# M0519AE_v1 register map
File version: 1.0
Registers are 32-bit, read-write, reset 0x0 unless marked. A register's access mark holds for its fields unless they carry their own. Offsets are from the block's base; [hi:lo] are bit positions; {n}, {i} and the like mark numbered series.

## CLK — CLK Register Map
Base 0x50000200
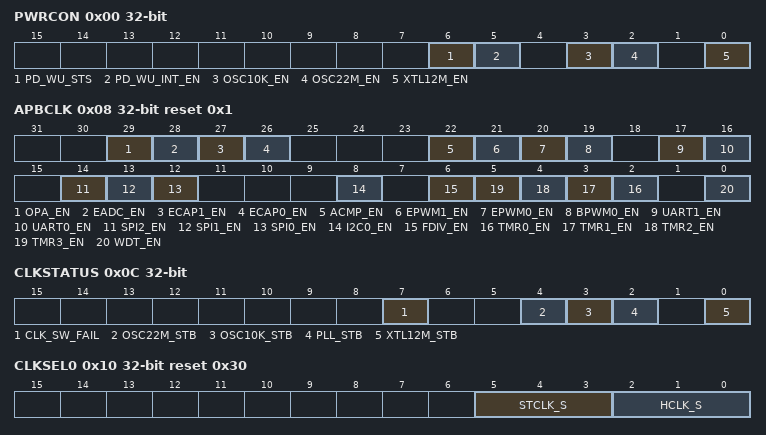
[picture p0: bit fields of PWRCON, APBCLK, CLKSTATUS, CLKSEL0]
0x00 PWRCON (reset mask 0xFFFFFFF0) — System Power-down Control Register
  [6] PD_WU_STS — Power-down Mode Wake-up Interrupt Status. Set by "power down wake up event", it indicates that resume from Power-down mode. Write 1 to clear the bit to zero. Note: This bit is working only if PD_WU_INT_EN (PWRCON[5]) set to 1.
  [5] PD_WU_INT_EN — Power-down Mode Wake-up Interrupt Enable Bit (Write Protect). Note1: The interrupt will occur when both PD_WU_STS and PD_WU_INT_EN are high. Note2: This bit is write protected bit. Refer to the REGWRPROT register.
    0=Power-down mode wake-up interrupt Disabled; 1=Power-down mode wake-up interrupt Enabled
  [3] OSC10K_EN — Internal 10 kHz Oscillator Enable Bit (Write Protect). Note: This bit is write protected bit. Refer to the REGWRPROT register.
    0=10 kHz Oscillation Disabled; 1=10 kHz Oscillation Enabled
  [2] OSC22M_EN — Internal 22.1184 MHz Oscillator Enable Bit (Write Protect). Note: This bit is write protected bit. Refer to the REGWRPROT register.
    0=22.1184 MHz Oscillation Disabled; 1=22.1184 MHz Oscillation Enabled
  [0] XTL12M_EN — External 4~24 MHz Crystal Enable Bit (Write Protect). The bit default value is set by flash controller user configuration register CFOSC (Config0[26:24]). When the default clock source is from external 4~24 MHz crystal, this bit is set to 1 automatically. Note: This bit is write protected bit. Refer to the REGWRPROT register.
    0=External 4~24 MHz crystal Disabled; 1=External 4~24 MHz crystal Enabled
0x04 AHBCLK reset 0x5 — AHB Devices Clock Enable Control Register
  [4] HDIV_EN — Hardware Divider Controller Clock Enable Bit
    0=Hardware Divider engine clock Disabled; 1=Hardware Divider engine clock Enabled
0x08 APBCLK reset 0x1 — APB Devices Clock Enable Control Register
  [29] OPA_EN — OPA0 and OPA1 Clock Enable Bit
    0=OPA0 and OPA1 clock Disabled; 1=OPA0 and OPA1 clock Enabled
  [28] EADC_EN — EADC Clock Enable Bit
    0=EADC clock Disabled; 1=EADC clock Enabled
  [27] ECAP1_EN — Enhanced Input Capture 1 Clock Enable Bit
    0=Enhanced input capture 1 clock Disabled; 1=Enhanced input capture 1 clock Enabled
  [26] ECAP0_EN — Enhanced Input Capture 0 Clock Enable Bit
    0=Enhanced input capture 0 clock Disabled; 1=Enhanced input capture 0 clock Enabled
  [22] ACMP_EN — Analog Comparator Clock Enable Bit
    0=Analog comparator clock Disabled; 1=Analog comparator clock Enabled
  [21] EPWM1_EN — Enhanced PWM1 Clock Enable Bit
    0=Enhanced PWM1 clock Disabled; 1=Enhanced PWM1 clock Enabled
  [20] EPWM0_EN — Enhanced PWM0 Clock Enable Bit
    0=Enhanced PWM0 clock Disabled; 1=Enhanced PWM0 clock Enabled
  [19] BPWM0_EN — Basic PWM0 Clock Enable Bit
    0=Basic PWM0 clock Disabled; 1=Basic PWM0 clock Enabled
  [17] UART1_EN — UART1 Clock Enable Bit
    0=UART1 clock Disabled; 1=UART1 clock Enabled
  [16] UART0_EN — UART0 Clock Enable Bit
    0=UART0 clock Disabled; 1=UART0 clock Enabled
  [14] SPI2_EN — SPI2 Clock Enable Bit
    0=SPI2 clock Disabled; 1=SPI2 clock Enabled
  [13] SPI1_EN — SPI1 Clock Enable Bit
    0=SPI1 clock Disabled; 1=SPI1 clock Enabled
  [12] SPI0_EN — SPI0 Clock Enable Bit
    0=SPI0 clock Disabled; 1=SPI0 clock Enabled
  [8] I2C0_EN — I2C0 Clock Enable Bit
    0=I2C0 clock Disabled; 1=I2C0 clock Enabled
  [6] FDIV_EN — Frequency Divider Output Clock Enable Bit
    0=Frequency divider output clock Disabled; 1=Frequency divider output clock Enabled
  [n+2] TMR{n}_EN (n=0..3) — Timer{n} Clock Enable Bit
    0=Timer{n} clock Disabled; 1=Timer{n} clock Enabled
  [0] WDT_EN — Watchdog Timer Clock Enable Bit (Write Protect). Note: This bit is write protected bit. Refer to the REGWRPROT register.
    0=Watchdog Timer clock Disabled; 1=Watchdog Timer clock Enabled
0x0C CLKSTATUS ro (reset mask 0xFFFFFF00) — Clock Status Monitor Register
  [7] CLK_SW_FAIL — Clock Switching Fail Flag (Read Only). This bit is an index that if current system clock source is match as user defined at HCLK_S (CLKSEL0[2:0]). When user switch system clock, the system clock source will keep old clock until the new clock is stable. During the period that waiting new clock stable, this bit will be an index shows system clock source is not match as user wanted.
    0=Clock switching success; 1=Clock switching failure
  [4] OSC22M_STB — Internal 22.1184M Hz Oscillator Clock Source Stable Flag (Read Only)
    0=Internal 22.1184M Hz oscillator clock is not stable or disabled; 1=Internal 22.1184M Hz oscillator clock is stable and enabled
  [3] OSC10K_STB — Internal 10k Hz Clock Source Stable Flag (Read Only)
    0=Internal 10k Hz oscillator clock is not stable or disabled; 1=Internal 10k Hz oscillator clock is stable and enabled
  [2] PLL_STB — PLL Clock Source Stable Flag (Read Only)
    0=PLL clock is not stable or disabled; 1=PLL clock is stable in normal mode
  [0] XTL12M_STB — External 4~24 MHz Crystal Clock Source Stable Flag (Read Only)
    0=External 4~24 MHz crystal clock is not stable or disabled; 1=External 4~24 MHz crystal clock is stable and enabled
0x10 CLKSEL0 reset 0x30 (reset mask 0xFFFFFFF0) — Clock Source Select Control Register 0
  [5:3] STCLK_S — Cortex-M0 SysTick Clock Source Selection (Write Protect)
    0=Clock source from external 4~24 MHz crystal clock; 2=Clock source from external 4~24 MHz crystal clock/2; 3=Clock source from HCLK/2; 7=Clock source from internal 22.1184 MHz oscillator clock/2
  [2:0] HCLK_S — HCLK Clock Source Selection (Write Protect). Before clock switching, the related clock sources (both pre-select and new-select) must be turn on. The 3-bit default value is reloaded from the value of CFOSC (Config0[26:24]) in user configuration register of Flash controller by any reset. Therefore the default value is either 000b or 111b. Note: These bits are write protected bits. Refer to the REGWRPROT register.
    0=Clock source from external 4~24 MHz crystal clock; 2=Clock source from PLL clock; 3=Clock source from internal 10 kHz oscillator clock; 7=Clock source from internal 22.1184 MHz oscillator clock
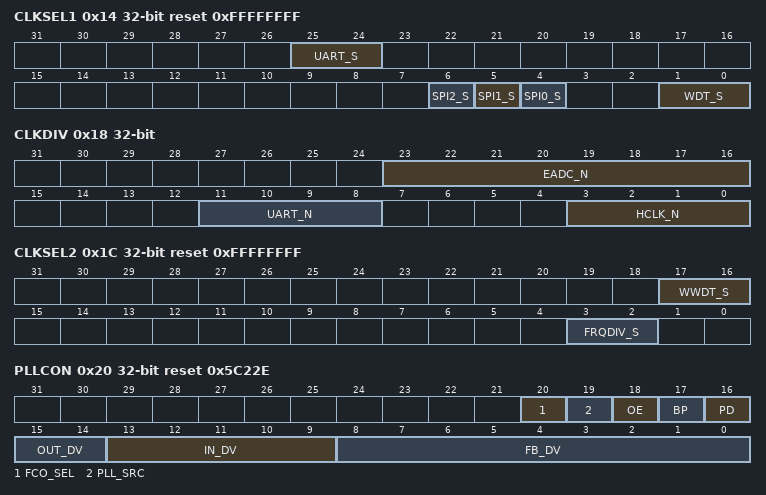
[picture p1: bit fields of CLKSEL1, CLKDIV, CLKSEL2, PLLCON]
0x14 CLKSEL1 reset 0xFFFFFFFF — Clock Source Select Control Register 1
  [25:24] UART_S — UART Clock Source Selection
    0=Clock source from external 4~24 MHz crystal clock; 1=Clock source from PLL clock; 3=Clock source from internal 22.1184 MHz oscillator clock
  [6] SPI2_S — SPI2 Clock Source Selection
    0=Clock source from PLL clock; 1=Clock source from HCLK
  [5] SPI1_S — SPI1 Clock Source Selection
    0=Clock source from PLL clock; 1=Clock source from HCLK
  [4] SPI0_S — SPI0 Clock Source Selection
    0=Clock source from PLL clock; 1=Clock source from HCLK
  [1:0] WDT_S — Watchdog Timer Clock Source Selection (Write Protect). Note: These bits are write protected bits. Refer to the REGWRPROT register.
    0=Clock source from HCLK/128 clock; 1=Clock source from HCLK/512 clock; 2=Clock source from HCLK/2048 clock; 3=Clock source from internal 10 kHz oscillator clock
0x18 CLKDIV — Clock Divider Number Register
  [23:16] EADC_N — EADC Clock Divider
  [11:8] UART_N — UART Clock Divider
  [3:0] HCLK_N — HCLK Clock Divider
0x1C CLKSEL2 reset 0xFFFFFFFF — Clock Source Select Control Register 2
  [17:16] WWDT_S — Window Watchdog Timer Clock Source Selection
    2=Clock source from HCLK/2048 clock; 3=Clock source from internal 10 kHz low speed oscillator clock
  [3:2] FRQDIV_S — Clock Divider Clock Source Selection
    0=Clock source from external 4~24 MHz crystal clock; 2=Clock source from HCLK; 3=Clock source from internal 22.1184 MHz oscillator clock
0x20 PLLCON reset 0x5C22E — PLL Control Register
  [20] FCO_SEL — PLL FCO Selection
    0=When the FCO frequency range between 100MHz and 200MHz, this bit should be set as 0; 1=When the FCO frequency range between 200MHz to 500MHz, this bit should be set as 1
  [19] PLL_SRC — PLL Source Clock Selection
    0=PLL source clock from external 4~24 MHz crystal; 1=PLL source clock from internal 22.1184 MHz oscillator
  [18] OE — PLL OE (FOUT Enable) Bit
    0=PLL FOUT enable; 1=PLL FOUT is fixed low
  [17] BP — PLL Bypass Control
    0=PLL is in normal mode (default); 1=PLL clock output is same as clock input
  [16] PD — Power-down Mode
    0=PLL is in normal mode; 1=PLL is in power-down mode (default)
  [15:14] OUT_DV — PLL Output Divider Control Bits. Refer to the formulas below the table.
  [13:9] IN_DV — PLL Input Divider Control Bits. Refer to the formulas below the table.
  [8:0] FB_DV — PLL Feedback Divider Control Bits. Refer to the formulas below the table.
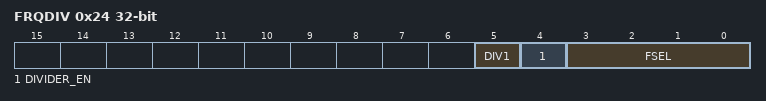
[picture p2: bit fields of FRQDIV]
0x24 FRQDIV — Frequency Divider Control Register
  [5] DIV1 — Frequency Divider Divide 1 Enable Bit
    0=Frequency divider will output clock with source frequency divide by FSEL; 1=Frequency divider will output clock with source frequency
  [4] DIVIDER_EN — Frequency Divider Enable Bit
    0=Frequency divider Disabled; 1=Frequency divider Enabled
  [3:0] FSEL — Frequency Divider Output Selection Bits. The output formula is: where FFRQDIV_CLK is the input clock frequency, FCLKO is the clock divider output frequency and N is the 4-bit value in FSEL[3:0].
